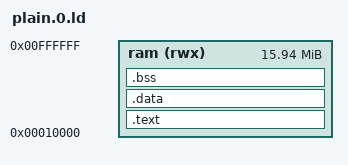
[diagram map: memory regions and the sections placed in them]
ENTRY(Vector_Init);

MEMORY
{
	ram (rwx) : ORIGIN = 0x0010000, LENGTH = ( 16M - 0x10000 )
}

PROVIDE(__stack = 0x0010000);

SECTIONS
{
    .text :
    {
        _text = .;
        __isr_vector_start = .;
        *(.isr_vector)
        __isr_vector_end = .;
        *(.text*)
        *(.rodata*)
        _etext = .;
    } > ram
    .data : /*AT(ADDR(.text) + SIZEOF(.text))*/
    {
        _data = .;
        *(vtable)
        *(.data*)
        _edata = .;
    } > ram
    .bss :
    {
        _bss = .;
        *(.bss*)
        *(COMMON)
        _ebss = .;
    } > ram
}

